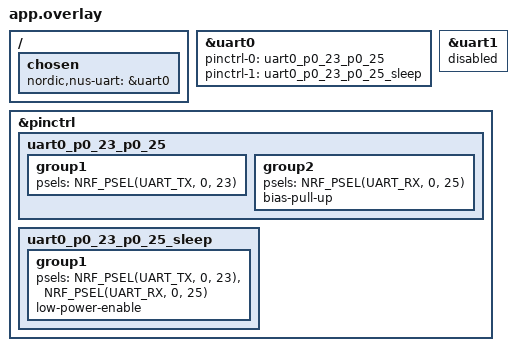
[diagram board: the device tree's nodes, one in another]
/*
 * Copyright (c) 2022 Nordic Semiconductor ASA
 *
 * SPDX-License-Identifier: LicenseRef-Nordic-5-Clause
 */

/ {
	chosen {
		nordic,nus-uart = &uart0;
	};
};

/* NUS UART on P0.23 (TX), P0.25 (RX). P0.19/P0.21 are used by network core UART. */
&uart0 {
	status = "okay";
	pinctrl-0 = <&uart0_p0_23_p0_25>;
	pinctrl-1 = <&uart0_p0_23_p0_25_sleep>;
	pinctrl-names = "default", "sleep";
};

/* UART1 (Arduino / P1.00–P1.01) disabled to release P1.00 and P1.01 for the switch */
&uart1 {
	status = "disabled";
};

&pinctrl {
	uart0_p0_23_p0_25: uart0_p0_23_p0_25 {
		group1 {
			psels = <NRF_PSEL(UART_TX, 0, 23)>;
		};
		group2 {
			psels = <NRF_PSEL(UART_RX, 0, 25)>;
			bias-pull-up;
		};
	};

	uart0_p0_23_p0_25_sleep: uart0_p0_23_p0_25_sleep {
		group1 {
			psels = <NRF_PSEL(UART_TX, 0, 23)>,
				<NRF_PSEL(UART_RX, 0, 25)>;
			low-power-enable;
		};
	};
};
